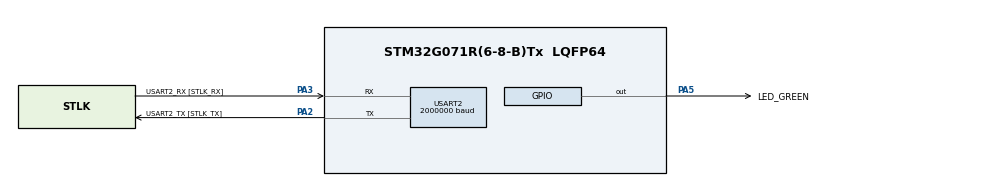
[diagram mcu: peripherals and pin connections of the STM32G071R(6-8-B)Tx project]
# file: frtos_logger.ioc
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FREERTOS.MEMORY_ALLOCATION=1
FREERTOS.Tasks01=logger_th,-2,256,entry_logger_thread,Default,NULL,Static,logger_th_buffer,logger_th_cb;demo_th,0,128,entry_demo_th,Default,NULL,Static,demo_th_buffer,demo_th_cb;vcp_th,-3,128,entry_vcp_th,Default,NULL,Static,vcpThBuffer,vcpThCb
FREERTOS.configENABLE_BACKWARD_COMPATIBILITY=0
FREERTOS.configRECORD_STACK_HIGH_ADDRESS=1
Mcu.Family=STM32G0
Mcu.Name=STM32G071R(6-8-B)Tx
Mcu.Package=LQFP64
NVIC.TIM17_IRQn=true\:3\:0\:false\:false\:true\:false\:false\:true
NVIC.TimeBase=TIM17_IRQn
NVIC.TimeBaseIP=TIM17
PA13.GPIO_Label=TMS
PA13.Mode=Serial_Wire
PA13.Signal=SYS_SWDIO
PA14-BOOT0.GPIO_Label=TCK
PA14-BOOT0.Mode=Serial_Wire
PA14-BOOT0.Signal=SYS_SWCLK
PA2.GPIO_Label=USART2_TX [STLK_TX]
PA2.GPIO_PuPd=GPIO_PULLUP
PA2.Mode=Asynchronous
PA2.Signal=USART2_TX
PA3.GPIO_Label=USART2_RX [STLK_RX]
PA3.GPIO_PuPd=GPIO_PULLUP
PA3.Mode=Asynchronous
PA3.Signal=USART2_RX
PA5.GPIO_Label=LED_GREEN
PA5.GPIO_Speed=GPIO_SPEED_FREQ_HIGH
PA5.Signal=GPIO_Output
PC13.Mode=SYS_WakeUp1
PC13.Signal=SYS_WKUP2
PC14-OSC32_IN\ (PC14).Mode=LSE-External-Oscillator
PC14-OSC32_IN\ (PC14).Signal=RCC_OSC32_IN
PC15-OSC32_OUT\ (PC15).Mode=LSE-External-Oscillator
PC15-OSC32_OUT\ (PC15).Signal=RCC_OSC32_OUT
PF0-OSC_IN\ (PF0).GPIO_Label=MCO
PF0-OSC_IN\ (PF0).Mode=HSE-External-Clock-Source
PF0-OSC_IN\ (PF0).Signal=RCC_OSC_IN
ProjectManager.HeapSize=0x200
ProjectManager.StackSize=0x400
ProjectManager.TargetToolchain=STM32CubeIDE
RCC.ADCFreq_Value=64000000
RCC.AHBFreq_Value=64000000
RCC.CortexFreq_Value=64000000
RCC.EXTERNAL_CLOCK_VALUE=12288000
RCC.HCLKFreq_Value=64000000
RCC.HSE_VALUE=8000000
RCC.HSI_VALUE=16000000
RCC.SYSCLKFreq_VALUE=64000000
RCC.SYSCLKSource=RCC_SYSCLKSOURCE_PLLCLK
RCC.VCOOutputFreq_Value=128000000
USART2.BaudRate=2000000
USART2.OverSampling=UART_OVERSAMPLING_8
USART2.VirtualMode-Asynchronous=VM_ASYNC
VP_FREERTOS_VS_CMSIS_V1.Mode=CMSIS_V1
VP_SYS_VS_DBSignals.Mode=DisableDeadBatterySignals
VP_SYS_VS_tim17.Mode=TIM17
VP_TIM2_VS_ClockSourceINT.Mode=Internal
board=NUCLEO-G071RB

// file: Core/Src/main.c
/* USER CODE BEGIN Header */
/**
  ******************************************************************************
  * @file           : main.c
  * @brief          : Main program body
  ******************************************************************************
  * @attention
  *
  * <h2><center>&copy; Copyright (c) 2021 STMicroelectronics.
  * All rights reserved.</center></h2>
  *
  * This software component is licensed by ST under BSD 3-Clause license,
  * the "License"; You may not use this file except in compliance with the
  * License. You may obtain a copy of the License at:
  *                        opensource.org/licenses/BSD-3-Clause
  *
  ******************************************************************************
  */
/* USER CODE END Header */
#include "main.h"
#include "cmsis_os.h"

/* USER CODE BEGIN Includes */
#include "log.h"
#include "vcp.h"
/* USER CODE END Includes */

TIM_HandleTypeDef htim2;

UART_HandleTypeDef huart2;

osThreadId logger_thHandle;
uint32_t logger_th_buffer[ 256 ];
osStaticThreadDef_t logger_th_cb;
osThreadId demo_thHandle;
uint32_t demo_th_buffer[ 128 ];
osStaticThreadDef_t demo_th_cb;
osThreadId vcp_thHandle;
uint32_t vcpThBuffer[ 128 ];
osStaticThreadDef_t vcpThCb;

void SystemClock_Config(void);
static void MX_GPIO_Init(void);
static void MX_USART2_UART_Init(void);
static void MX_TIM2_Init(void);
void entry_logger_thread(void const * argument);
void entry_demo_th(void const * argument);
void entry_vcp_th(void const * argument);

/* USER CODE BEGIN 0 */

void log_cb_backend_flush(void)
{
  vcp_flush();
}

void log_cb_backend_write(char* str, uint32_t length)
{
  vcp_send(str, length);
}

/* USER CODE END 0 */

int main(void)
{

  /* MCU Configuration--------------------------------------------------------*/

  /* Reset of all peripherals, Initializes the Flash interface and the Systick. */
  HAL_Init();

  /* Configure the system clock */
  SystemClock_Config();

  /* Initialize all configured peripherals */
  MX_GPIO_Init();
  MX_USART2_UART_Init();
  MX_TIM2_Init();

  /* Create the thread(s) */
  /* definition and creation of logger_th */
  osThreadStaticDef(logger_th, entry_logger_thread, osPriorityLow, 0, 256, logger_th_buffer, &logger_th_cb);
  logger_thHandle = osThreadCreate(osThread(logger_th), NULL);

  /* definition and creation of demo_th */
  osThreadStaticDef(demo_th, entry_demo_th, osPriorityNormal, 0, 128, demo_th_buffer, &demo_th_cb);
  demo_thHandle = osThreadCreate(osThread(demo_th), NULL);

  /* definition and creation of vcp_th */
  osThreadStaticDef(vcp_th, entry_vcp_th, osPriorityIdle, 0, 128, vcpThBuffer, &vcpThCb);
  vcp_thHandle = osThreadCreate(osThread(vcp_th), NULL);

  /* USER CODE BEGIN RTOS_THREADS */
  vcp_init(&huart2);
  log_init();

  /* USER CODE END RTOS_THREADS */

  /* Start scheduler */
  osKernelStart();

  /* We should never get here as control is now taken by the scheduler */
  /* Infinite loop */
  while (1)
  {

  }
}

void SystemClock_Config(void)
{
  LL_FLASH_SetLatency(LL_FLASH_LATENCY_2);
  while(LL_FLASH_GetLatency() != LL_FLASH_LATENCY_2)
  {
  }

  /* HSI configuration and activation */
  LL_RCC_HSI_Enable();
  while(LL_RCC_HSI_IsReady() != 1)
  {
  }

  /* Main PLL configuration and activation */
  LL_RCC_PLL_ConfigDomain_SYS(LL_RCC_PLLSOURCE_HSI, LL_RCC_PLLM_DIV_1, 8, LL_RCC_PLLR_DIV_2);
  LL_RCC_PLL_Enable();
  LL_RCC_PLL_EnableDomain_SYS();
  while(LL_RCC_PLL_IsReady() != 1)
  {
  }

  /* Set AHB prescaler*/
  LL_RCC_SetAHBPrescaler(LL_RCC_SYSCLK_DIV_1);

  /* Sysclk activation on the main PLL */
  LL_RCC_SetSysClkSource(LL_RCC_SYS_CLKSOURCE_PLL);
  while(LL_RCC_GetSysClkSource() != LL_RCC_SYS_CLKSOURCE_STATUS_PLL)
  {
  }

  /* Set APB1 prescaler*/
  LL_RCC_SetAPB1Prescaler(LL_RCC_APB1_DIV_1);
  /* Update CMSIS variable (which can be updated also through SystemCoreClockUpdate function) */
  LL_SetSystemCoreClock(64000000);

   /* Update the time base */
  if (HAL_InitTick (TICK_INT_PRIORITY) != HAL_OK)
  {
    Error_Handler();
  }
  LL_RCC_SetUSARTClockSource(LL_RCC_USART2_CLKSOURCE_PCLK1);
}

static void MX_TIM2_Init(void)
{

  TIM_ClockConfigTypeDef sClockSourceConfig = {0};
  TIM_MasterConfigTypeDef sMasterConfig = {0};

  htim2.Instance = TIM2;
  htim2.Init.Prescaler = 0;
  htim2.Init.CounterMode = TIM_COUNTERMODE_UP;
  htim2.Init.Period = 4294967295;
  htim2.Init.ClockDivision = TIM_CLOCKDIVISION_DIV1;
  htim2.Init.AutoReloadPreload = TIM_AUTORELOAD_PRELOAD_DISABLE;
  if (HAL_TIM_Base_Init(&htim2) != HAL_OK)
  {
    Error_Handler();
  }
  sClockSourceConfig.ClockSource = TIM_CLOCKSOURCE_INTERNAL;
  if (HAL_TIM_ConfigClockSource(&htim2, &sClockSourceConfig) != HAL_OK)
  {
    Error_Handler();
  }
  sMasterConfig.MasterOutputTrigger = TIM_TRGO_RESET;
  sMasterConfig.MasterSlaveMode = TIM_MASTERSLAVEMODE_DISABLE;
  if (HAL_TIMEx_MasterConfigSynchronization(&htim2, &sMasterConfig) != HAL_OK)
  {
    Error_Handler();
  }

}

static void MX_USART2_UART_Init(void)
{

  huart2.Instance = USART2;
  huart2.Init.BaudRate = 2000000;
  huart2.Init.WordLength = UART_WORDLENGTH_8B;
  huart2.Init.StopBits = UART_STOPBITS_1;
  huart2.Init.Parity = UART_PARITY_NONE;
  huart2.Init.Mode = UART_MODE_TX_RX;
  huart2.Init.HwFlowCtl = UART_HWCONTROL_NONE;
  huart2.Init.OverSampling = UART_OVERSAMPLING_8;
  huart2.Init.OneBitSampling = UART_ONE_BIT_SAMPLE_DISABLE;
  huart2.Init.ClockPrescaler = UART_PRESCALER_DIV1;
  huart2.AdvancedInit.AdvFeatureInit = UART_ADVFEATURE_NO_INIT;
  if (HAL_UART_Init(&huart2) != HAL_OK)
  {
    Error_Handler();
  }
  if (HAL_UARTEx_SetTxFifoThreshold(&huart2, UART_TXFIFO_THRESHOLD_1_8) != HAL_OK)
  {
    Error_Handler();
  }
  if (HAL_UARTEx_SetRxFifoThreshold(&huart2, UART_RXFIFO_THRESHOLD_1_8) != HAL_OK)
  {
    Error_Handler();
  }
  if (HAL_UARTEx_DisableFifoMode(&huart2) != HAL_OK)
  {
    Error_Handler();
  }

}

static void MX_GPIO_Init(void)
{
  GPIO_InitTypeDef GPIO_InitStruct = {0};

  /* GPIO Ports Clock Enable */
  __HAL_RCC_GPIOC_CLK_ENABLE();
  __HAL_RCC_GPIOF_CLK_ENABLE();
  __HAL_RCC_GPIOA_CLK_ENABLE();
  __HAL_RCC_GPIOB_CLK_ENABLE();
  __HAL_RCC_GPIOD_CLK_ENABLE();

  /*Configure GPIO pin Output Level */
  HAL_GPIO_WritePin(LED_GREEN_GPIO_Port, LED_GREEN_Pin, GPIO_PIN_RESET);

  /*Configure GPIO pins : PC11 PC12 PC0 PC1
                           PC2 PC3 PC4 PC5
                           PC6 PC7 PC8 PC9
                           PC10 */
  GPIO_InitStruct.Pin = GPIO_PIN_11|GPIO_PIN_12|GPIO_PIN_0|GPIO_PIN_1
                          |GPIO_PIN_2|GPIO_PIN_3|GPIO_PIN_4|GPIO_PIN_5
                          |GPIO_PIN_6|GPIO_PIN_7|GPIO_PIN_8|GPIO_PIN_9
                          |GPIO_PIN_10;
  GPIO_InitStruct.Mode = GPIO_MODE_ANALOG;
  GPIO_InitStruct.Pull = GPIO_NOPULL;
  HAL_GPIO_Init(GPIOC, &GPIO_InitStruct);

  /*Configure GPIO pins : PF1 PF2 */
  GPIO_InitStruct.Pin = GPIO_PIN_1|GPIO_PIN_2;
  GPIO_InitStruct.Mode = GPIO_MODE_ANALOG;
  GPIO_InitStruct.Pull = GPIO_NOPULL;
  HAL_GPIO_Init(GPIOF, &GPIO_InitStruct);

  /*Configure GPIO pins : PA0 PA1 PA4 PA6
                           PA7 PA8 PA9 PA10
                           PA11 PA12 PA15 */
  GPIO_InitStruct.Pin = GPIO_PIN_0|GPIO_PIN_1|GPIO_PIN_4|GPIO_PIN_6
                          |GPIO_PIN_7|GPIO_PIN_8|GPIO_PIN_9|GPIO_PIN_10
                          |GPIO_PIN_11|GPIO_PIN_12|GPIO_PIN_15;
  GPIO_InitStruct.Mode = GPIO_MODE_ANALOG;
  GPIO_InitStruct.Pull = GPIO_NOPULL;
  HAL_GPIO_Init(GPIOA, &GPIO_InitStruct);

  /*Configure GPIO pin : LED_GREEN_Pin */
  GPIO_InitStruct.Pin = LED_GREEN_Pin;
  GPIO_InitStruct.Mode = GPIO_MODE_OUTPUT_PP;
  GPIO_InitStruct.Pull = GPIO_NOPULL;
  GPIO_InitStruct.Speed = GPIO_SPEED_FREQ_HIGH;
  HAL_GPIO_Init(LED_GREEN_GPIO_Port, &GPIO_InitStruct);

  /*Configure GPIO pins : PB0 PB1 PB2 PB10
                           PB11 PB12 PB13 PB14
                           PB15 PB3 PB4 PB5
                           PB6 PB7 PB8 PB9 */
  GPIO_InitStruct.Pin = GPIO_PIN_0|GPIO_PIN_1|GPIO_PIN_2|GPIO_PIN_10
                          |GPIO_PIN_11|GPIO_PIN_12|GPIO_PIN_13|GPIO_PIN_14
                          |GPIO_PIN_15|GPIO_PIN_3|GPIO_PIN_4|GPIO_PIN_5
                          |GPIO_PIN_6|GPIO_PIN_7|GPIO_PIN_8|GPIO_PIN_9;
  GPIO_InitStruct.Mode = GPIO_MODE_ANALOG;
  GPIO_InitStruct.Pull = GPIO_NOPULL;
  HAL_GPIO_Init(GPIOB, &GPIO_InitStruct);

  /*Configure GPIO pins : PD8 PD9 PD0 PD1
                           PD2 PD3 PD4 PD5
                           PD6 */
  GPIO_InitStruct.Pin = GPIO_PIN_8|GPIO_PIN_9|GPIO_PIN_0|GPIO_PIN_1
                          |GPIO_PIN_2|GPIO_PIN_3|GPIO_PIN_4|GPIO_PIN_5
                          |GPIO_PIN_6;
  GPIO_InitStruct.Mode = GPIO_MODE_ANALOG;
  GPIO_InitStruct.Pull = GPIO_NOPULL;
  HAL_GPIO_Init(GPIOD, &GPIO_InitStruct);

}

void entry_logger_thread(void const * argument)
{
  /* USER CODE BEGIN 5 */
  log_thread(argument);
  /* USER CODE END 5 */
}

void entry_demo_th(void const * argument)
{
  /* USER CODE BEGIN entry_demo_th */
    volatile uint32_t exec_time;
    HAL_TIM_Base_Start(&htim2);

  /* Infinite loop */
  for(;;)
  {
      uint8_t  array8[4]   = {0, 25, 120, 255};
      uint16_t array16[4]  = {0, 500, 16000, 65000};
      uint32_t array32[4]  = {0, 25000, 150000, 4200230000};
      int16_t  arrays16[4] = {0, -500, -16000, INT16_MIN};
      int32_t  arrays32[4] = {0, -25000, -150000, INT32_MIN};

      uint8_t  arrayh8[4]   = {0, 25, 120, 255};
      uint16_t arrayh16[4]  = {0, 500, 16000, 65000};
      uint32_t arrayh32[4]  = {0, 25000, 150000, 4200230000};

      (void)exec_time;

      log_str("Test start\r\n");
      log_str("Tst0 \r\n");
      log_str("Tst1\r\n");
      log_str("Tst2\r\n");

      log_flush();

      log_array_udec(array8, 4);
      log_char('\r');
      log_char('\n');
      log_array_udec(array16, 4);
      log_char('\r');
      log_char('\n');
      log_array_udec(array32, 4);
      log_char('\r');
      log_char('\n');
      log_array_udec(arrays16, 4);
      log_char('\r');
      log_char('\n');
      log_array_udec(arrays32, 4);
      log_char('\r');
      log_char('\n');
      log_array_hex(arrayh8, 4);
      log_char('\r');
      log_char('\n');
      log_array_hex(arrayh16, 4);
      log_char('\r');
      log_char('\n');
      log_array_hex(arrayh32, 4);
      log_char('\r');
      log_char('\n');
      log_char('\r');
      log_char('\n');

      log_udec(0);
      log_char('\r');
      log_char('\n');
      log_udec(100);
      log_char('\r');
      log_char('\n');
      log_udec(123);
      log_char('\r');
      log_char('\n');
      log_udec(12345);
      log_char('\r');
      log_char('\n');
      log_udec(1234567890);
      log_char('\r');
      log_char('\n');

      log_hex((uint8_t)0x12);
      log_char('\r');
      log_char('\n');
      log_hex((uint16_t)0x1234);
      log_char('\r');
      log_char('\n');
      log_hex((uint32_t)0x123456);
      log_char('\r');
      log_char('\n');
      log_hex((uint32_t)0x12345678);
      log_char('\r');
      log_char('\n');

      log_sdec(-123);
      log_char('\r');
      log_char('\n');
      log_sdec(-12345);
      log_char('\r');
      log_char('\n');
      log_sdec(-1234567890);
      log_char('\r');
      log_char('\n');
      log_sdec((int8_t)INT8_MIN);
      log_char('\r');
      log_char('\n');
      log_sdec((int16_t)INT16_MIN);
      log_char('\r');
      log_char('\n');
      log_sdec(INT32_MIN);
      log_char('\r');
      log_char('\n');

      logc_str(1, "Conditional positive\r\n");
      logc_udec(1, (uint8_t)123);
      log_char('\r');
      log_char('\n');
      logc_hex(1, (uint8_t)0x12);
      log_char('\r');
      log_char('\n');
      logc_udec(0, (uint8_t)88);
      logc_hex(0, (uint8_t)0x77);
      logc_str(1, "Conditional positive\r\n");
      logc_str(0, "Conditional negative\r\n");
      log_char('\r');
      log_char('\n');

      logc_char(1, 'a');
      log_char('\r');
      log_char('\n');
      logc_char(1, 'a');
      log_char('\r');
      log_char('\n');
      logc_array_udec(1, arrayh16, 2);
      log_char('\r');
      log_char('\n');
      logc_array_hex(1, arrayh16, 2);
      log_char('\r');
      log_char('\n');
      logc_array_udec(1, arrayh16, 2);
      log_char('\r');
      log_char('\n');
      logc_array_hex(1, arrayh16, 2);
      log_char('\r');
      log_char('\n');

      log_msg_start("labelStart");
      log_str("String inside label");
      log_msg_stop("labelStop");
      log_char('\r');
      log_char('\n');
      log_msg_start(NULL);
      log_str("Message with no label");
      log_msg_stop(NULL);
      log_char('\r');
      log_char('\n');
      log_str("Testing special character: ");
      log_str("Ñú, Melón, Sandía, ñÚ");
      log_char('\r');
      log_char('\n');

      osDelay(500);
  }
  /* USER CODE END entry_demo_th */
}

void entry_vcp_th(void const * argument)
{
  /* USER CODE BEGIN entry_vcp_th */
  vcp_th(argument);
  /* USER CODE END entry_vcp_th */
}

void HAL_TIM_PeriodElapsedCallback(TIM_HandleTypeDef *htim)
{
  if (htim->Instance == TIM17) {
    HAL_IncTick();
  }
}

void Error_Handler(void)
{
  __disable_irq();
  while (1)
  {
  }
}

/************************ (C) COPYRIGHT STMicroelectronics *****END OF FILE****/

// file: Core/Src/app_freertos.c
/* USER CODE BEGIN Header */
/**
  ******************************************************************************
  * File Name          : app_freertos.c
  * Description        : Code for freertos applications
  ******************************************************************************
  * @attention
  *
  * <h2><center>&copy; Copyright (c) 2021 STMicroelectronics.
  * All rights reserved.</center></h2>
  *
  * This software component is licensed by ST under Ultimate Liberty license
  * SLA0044, the "License"; You may not use this file except in compliance with
  * the License. You may obtain a copy of the License at:
  *                             www.st.com/SLA0044
  *
  ******************************************************************************
  */
/* USER CODE END Header */

#include "FreeRTOS.h"
#include "task.h"
#include "main.h"

/* GetIdleTaskMemory prototype (linked to static allocation support) */
void vApplicationGetIdleTaskMemory( StaticTask_t **ppxIdleTaskTCBBuffer, StackType_t **ppxIdleTaskStackBuffer, uint32_t *pulIdleTaskStackSize );

/* USER CODE BEGIN GET_IDLE_TASK_MEMORY */
static StaticTask_t xIdleTaskTCBBuffer;
static StackType_t xIdleStack[configMINIMAL_STACK_SIZE];

void vApplicationGetIdleTaskMemory( StaticTask_t **ppxIdleTaskTCBBuffer, StackType_t **ppxIdleTaskStackBuffer, uint32_t *pulIdleTaskStackSize )
{
  *ppxIdleTaskTCBBuffer = &xIdleTaskTCBBuffer;
  *ppxIdleTaskStackBuffer = &xIdleStack[0];
  *pulIdleTaskStackSize = configMINIMAL_STACK_SIZE;
  /* place for user code */
}
/* USER CODE END GET_IDLE_TASK_MEMORY */

/************************ (C) COPYRIGHT STMicroelectronics *****END OF FILE****/
